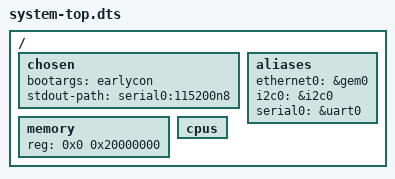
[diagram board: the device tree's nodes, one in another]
/*
 * CAUTION: This file is automatically generated by Xilinx.
 * Version:
 * Today is: Mon May 11 19:20:20 2020
 */


/dts-v1/;
#include "zynq-7000.dtsi"
#include "pl.dtsi"
#include "pcw.dtsi"
#include "skeleton.dtsi"
/ {
	chosen {
		bootargs = "earlycon";
		stdout-path = "serial0:115200n8";
	};
	aliases {
		ethernet0 = &gem0;
		i2c0 = &i2c0;
		serial0 = &uart0;
	};
	memory {
		device_type = "memory";
		reg = <0x0 0x20000000>;
	};
	cpus {
		/delete-node/ cpu@1 ;
	};
};
